VERSION "can-node / bms-node matrix v0.1"

NS_ :

BS_:

BU_: Node BMS Gateway Tester

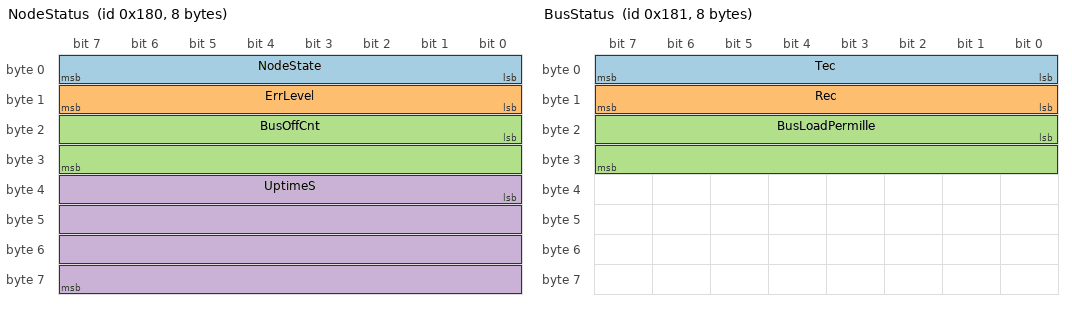
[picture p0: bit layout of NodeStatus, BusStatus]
BO_ 384 NodeStatus: 8 Node
 SG_ NodeState : 0|8@1+ (1,0) [0|3] "" Gateway
 SG_ ErrLevel : 8|8@1+ (1,0) [0|2] "" Gateway
 SG_ BusOffCnt : 16|16@1+ (1,0) [0|65535] "" Gateway
 SG_ UptimeS : 32|32@1+ (1,0) [0|4294967295] "s" Gateway

BO_ 385 BusStatus: 8 Node
 SG_ Tec : 0|8@1+ (1,0) [0|255] "" Gateway
 SG_ Rec : 8|8@1+ (1,0) [0|255] "" Gateway
 SG_ BusLoadPermille : 16|16@1+ (1,0) [0|1000] "permille" Gateway

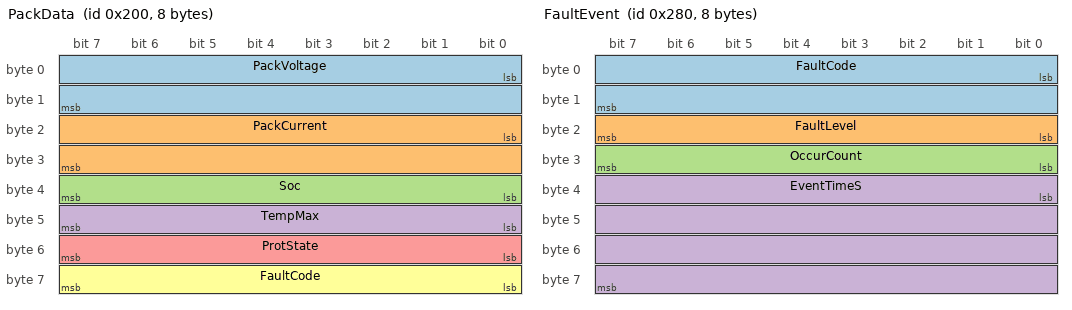
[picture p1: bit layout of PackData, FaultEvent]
BO_ 512 PackData: 8 BMS
 SG_ PackVoltage : 0|16@1+ (0.01,0) [0|655.35] "V" Gateway
 SG_ PackCurrent : 16|16@1- (0.01,0) [-327.68|327.67] "A" Gateway
 SG_ Soc : 32|8@1+ (1,0) [0|100] "%" Gateway
 SG_ TempMax : 40|8@1- (1,-40) [-40|215] "degC" Gateway
 SG_ ProtState : 48|8@1+ (1,0) [0|3] "" Gateway
 SG_ FaultCode : 56|8@1+ (1,0) [0|255] "" Gateway

BO_ 640 FaultEvent: 8 BMS
 SG_ FaultCode : 0|16@1+ (1,0) [0|65535] "" Gateway
 SG_ FaultLevel : 16|8@1+ (1,0) [0|3] "" Gateway
 SG_ OccurCount : 24|8@1+ (1,0) [0|255] "" Gateway
 SG_ EventTimeS : 32|32@1+ (1,0) [0|4294967295] "s" Gateway

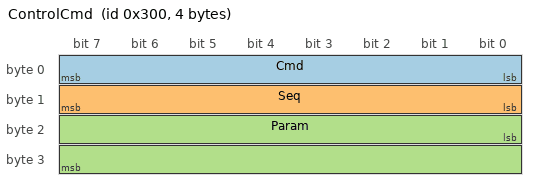
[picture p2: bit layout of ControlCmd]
BO_ 768 ControlCmd: 4 Gateway
 SG_ Cmd : 0|8@1+ (1,0) [1|3] "" Node,BMS
 SG_ Seq : 8|8@1+ (1,0) [0|255] "" Node,BMS
 SG_ Param : 16|16@1+ (1,0) [0|65535] "" Node,BMS

BA_DEF_ BO_ "GenMsgCycleTime" INT 0 65535;
BA_DEF_ BO_ "GenMsgSendType" ENUM "Cyclic","Event";
BA_DEF_DEF_ "GenMsgCycleTime" 0;
BA_DEF_DEF_ "GenMsgSendType" "Event";
BA_ "GenMsgSendType" BO_ 384 0;
BA_ "GenMsgCycleTime" BO_ 384 100;
BA_ "GenMsgSendType" BO_ 385 0;
BA_ "GenMsgCycleTime" BO_ 385 20;
BA_ "GenMsgSendType" BO_ 512 0;
BA_ "GenMsgCycleTime" BO_ 512 50;

VAL_ 384 NodeState 0 "Init" 1 "Normal" 2 "Degraded" 3 "Fault" ;
VAL_ 384 ErrLevel 0 "ErrorActive" 1 "ErrorPassive" 2 "BusOff" ;
VAL_ 512 ProtState 0 "Normal" 1 "Warning" 2 "Protect" 3 "Recover" ;
VAL_ 640 FaultLevel 0 "Info" 1 "Warning" 2 "Protect" 3 "Critical" ;
VAL_ 768 Cmd 1 "Start" 2 "Stop" 3 "ClearFault" ;

CM_ "Message definitions must stay in sync with can-node/docs/protocol.md. Bump the version on any change.";
CM_ BO_ 384 "Node state and heartbeat, 100ms cycle";
CM_ BO_ 385 "Bus error counters and load, 20ms cycle";
CM_ BO_ 512 "BMS pack data, 50ms cycle";
CM_ BO_ 640 "Fault event, sent on state transition";
CM_ BO_ 768 "Gateway control command, with sequence number";
CM_ SG_ 385 Tec "TX error counter, saturated at 255; read raw value via UDS 0x22";
CM_ SG_ 512 PackCurrent "Positive when charging, negative when discharging";
CM_ SG_ 768 Seq "Node reports the last handled sequence in NodeStatus";
